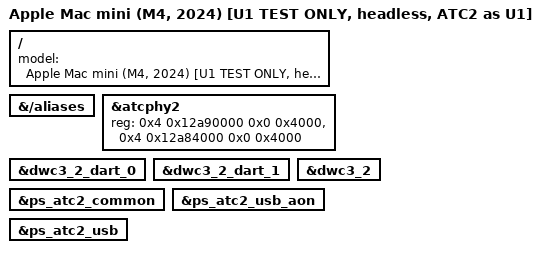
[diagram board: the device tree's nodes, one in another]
// SPDX-License-Identifier: GPL-2.0+ OR MIT
/*
 * TEST ONLY - not for upstream.
 *
 * A declared front-USB variable on top of the fully-off R1 headless tree:
 * ATC2 uses the USB2-only two-bank PHY form (usb2phy, pipehandler) proved by
 * U1, with no atcphy2 alias, so the loader injects no ATC tunables into it.
 * This is a fallback/later rung, not the R1 candidate.
 */

#include "t8132-j773g-u1-headless.dts"

/ {
	model = "Apple Mac mini (M4, 2024) [U1 TEST ONLY, headless, ATC2 as U1]";
};

&{/aliases} {
	/delete-property/ atcphy2;
};

&atcphy2 {
	reg = <0x4 0x12a90000 0x0 0x4000>,
	      <0x4 0x12a84000 0x0 0x4000>;
	reg-names = "usb2phy", "pipehandler";
	status = "okay";
};

&dwc3_2_dart_0 {
	status = "okay";
};

&dwc3_2_dart_1 {
	status = "okay";
};

&dwc3_2 {
	status = "okay";
};

&ps_atc2_common {
	status = "okay";
};

&ps_atc2_usb_aon {
	status = "okay";
};

&ps_atc2_usb {
	status = "okay";
};
